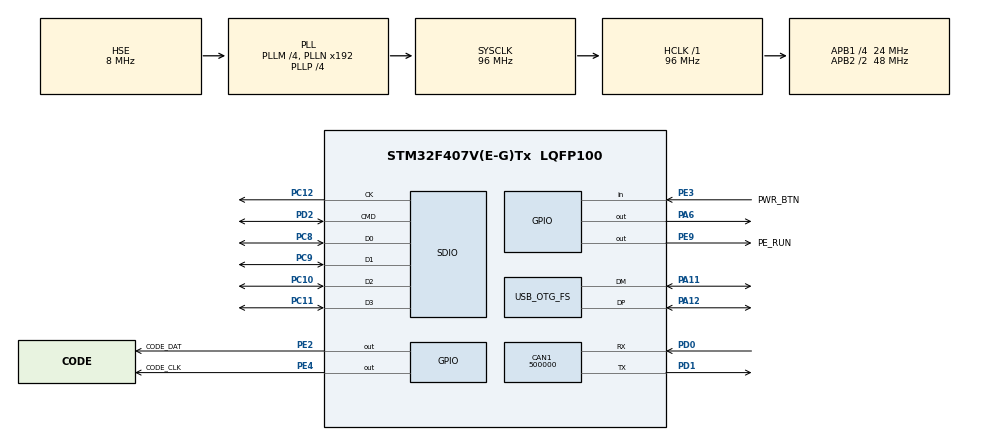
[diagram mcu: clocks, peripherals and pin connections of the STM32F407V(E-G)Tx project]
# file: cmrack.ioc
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Mcu.Family=STM32F4
PH0-OSC_IN.Signal=RCC_OSC_IN
RCC.CortexFreq_Value=96000000
PC12.Signal=SDIO_CK
PC10.Signal=SDIO_D2
PE2.GPIO_Speed=GPIO_SPEED_FREQ_HIGH
PE9.GPIO_Speed=GPIO_SPEED_FREQ_HIGH
PA11.Mode=Host_Only
RCC.SYSCLKSource=RCC_SYSCLKSOURCE_PLLCLK
ProjectManager.StackSize=0x400
VP_FREERTOS_VS_CMSIS_V2.Mode=CMSIS_V2
FREERTOS.configENABLE_FPU=1
PA12.Signal=USB_OTG_FS_DP
RCC.HCLKFreq_Value=96000000
RCC.APB2TimFreq_Value=96000000
PD0.Signal=CAN1_RX
USB_HOST0.BSP.ip=GPIO
RCC.AHBFreq_Value=96000000
PH0-OSC_IN.Mode=HSE-External-Oscillator
RCC.HSE_VALUE=8000000
NVIC.TIM8_TRG_COM_TIM14_IRQn=true\:0\:0\:false\:false\:true\:false\:false\:true
USB_OTG_FS.phy_itface=HCD_PHY_EMBEDDED
PE9.Signal=GPIO_Output
PA14.Mode=Serial_Wire
PE4.GPIO_Speed=GPIO_SPEED_FREQ_HIGH
PE4.GPIO_Label=CODE_CLK
PC9.Mode=mmc_4_bits_Wide_bus
PE2.Signal=GPIO_Output
VP_SYS_VS_tim14.Mode=TIM14
PE4.Signal=GPIO_Output
PH1-OSC_OUT.Mode=HSE-External-Oscillator
USB_HOST0.BSP.i2caddr=0
Mcu.Package=LQFP100
PA6.Signal=GPIO_Output
NVIC.TimeBase=TIM8_TRG_COM_TIM14_IRQn
RCC.EnbaleCSS=true
NVIC.OTG_FS_IRQn=true\:5\:0\:false\:false\:true\:true\:false\:true
NVIC.TimeBaseIP=TIM14
USB_OTG_FS.VirtualMode=Host_Only
PC11.Mode=mmc_4_bits_Wide_bus
USB_HOST0.BSP.name=Drive_VBUS_FS
RCC.APB2CLKDivider=RCC_HCLK_DIV2
RCC.APB1TimFreq_Value=48000000
CAN1.CalculateTimeBit=1999.99
PE2.GPIO_Label=CODE_DAT
CAN1.CalculateTimeQuantum=666.6666666666666
FREERTOS.Tasks01=defaultTask,24,128,StartDefaultTask,Default,NULL,Dynamic,NULL,NULL
PC11.Signal=SDIO_D3
CAN1.CalculateBaudRate=500000
PC8.Signal=SDIO_D0
USB_HOST0.BSP.solution=PA6
PC10.Mode=mmc_4_bits_Wide_bus
USB_HOST.BSP.number=1
PD1.Signal=CAN1_TX
RCC.APB1CLKDivider=RCC_HCLK_DIV4
USB_HOST0.BSP.STBoard=false
PA13.Signal=SYS_JTMS-SWDIO
CAN1.BS2=CAN_BS2_1TQ
CAN1.BS1=CAN_BS1_1TQ
ProjectManager.TargetToolchain=SW4STM32
USB_HOST.USBH_HandleTypeDef-ALL_Classes_FS=hUsbHostFS
RCC.LSE_VALUE=32768
PE9.GPIO_Label=PE_RUN
VP_FATFS_VS_Generic.Mode=User_defined
PD2.Mode=mmc_4_bits_Wide_bus
PC12.Mode=mmc_4_bits_Wide_bus
board=custom
RCC.VCOOutputFreq_Value=384000000
USB_HOST.VirtualModeFS=All_Classes
PD1.Mode=CAN_Activate
RCC.APB2Freq_Value=48000000
USB_HOST0.BSP.api=Unknown
PE3.GPIO_PuPd=GPIO_NOPULL
PH1-OSC_OUT.Signal=RCC_OSC_OUT
PA13.Mode=Serial_Wire
Mcu.Name=STM32F407V(E-G)Tx
PD0.Mode=CAN_Activate
PC8.Mode=mmc_4_bits_Wide_bus
RCC.48MHZClocksFreq_Value=48000000
RCC.SYSCLKFreq_VALUE=96000000
PA12.Mode=Host_Only
PA11.Signal=USB_OTG_FS_DM
PA14.Signal=SYS_JTCK-SWCLK
ProjectManager.HeapSize=0x200
RCC.HSI_VALUE=16000000
RCC.PLLP=RCC_PLLP_DIV4
RCC.PLLQ=8
NVIC.PriorityGroup=NVIC_PRIORITYGROUP_4
RCC.PLLM=4
PE3.Signal=GPIO_Input
PE3.GPIO_Label=PWR_BTN
PC9.Signal=SDIO_D1
PE9.GPIO_ModeDefaultOutputPP=GPIO_MODE_OUTPUT_OD
VP_USB_HOST_VS_USB_HOST_ALL_CLASS_FS.Mode=ALL_Classes_FS
PD2.Signal=SDIO_CMD
RCC.APB1Freq_Value=24000000
USB_HOST0.BSP.mode=Output
USB_HOST0.BSP.instance=PA6

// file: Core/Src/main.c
/* USER CODE BEGIN Header */
/**
  ******************************************************************************
  * @file           : main.c
  * @brief          : Main program body
  ******************************************************************************
  * @attention
  *
  * <h2><center>&copy; Copyright (c) 2021 STMicroelectronics.
  * All rights reserved.</center></h2>
  *
  * This software component is licensed by ST under Ultimate Liberty license
  * SLA0044, the "License"; You may not use this file except in compliance with
  * the License. You may obtain a copy of the License at:
  *                             www.st.com/SLA0044
  *
  ******************************************************************************
  */
/* USER CODE END Header */
#include <stm32f4xx_hal.h>
#include "main.h"
#include "cmsis_os.h"
#include "fatfs.h"
#include "usb_host.h"

CAN_HandleTypeDef hcan1;

MMC_HandleTypeDef hmmc;

/* Definitions for defaultTask */
osThreadId_t defaultTaskHandle;
const osThreadAttr_t defaultTask_attributes = {
        .name = "defaultTask",
        .priority = (osPriority_t) osPriorityNormal,
        .stack_size = 128 * 4
};

void SystemClock_Config(void);

static void MX_GPIO_Init(void);

static void MX_CAN1_Init(void);

static void MX_SDIO_MMC_Init(void);

void StartDefaultTask(void *argument) __noreturn;

int main(void) {

    /* MCU Configuration--------------------------------------------------------*/

    /* Reset of all peripherals, Initializes the Flash interface and the Systick. */
    HAL_Init();

    /* Configure the system clock */
    SystemClock_Config();

    /* USER CODE BEGIN SysInit */
    CLEAR_CODE();
    /* USER CODE END SysInit */

    /* Initialize all configured peripherals */
    MX_GPIO_Init();
    MX_CAN1_Init();
    MX_SDIO_MMC_Init();
    MX_FATFS_Init();

    /* USER CODE BEGIN 2 */
    write_code(1);
    HAL_Delay(100);
    /* USER CODE END 2 */

    /* Init scheduler */
    osKernelInitialize();

    /* Create the thread(s) */
    /* creation of defaultTask */
    defaultTaskHandle = osThreadNew(StartDefaultTask, NULL, &defaultTask_attributes);

    /* Start scheduler */
    osKernelStart();

    /* We should never get here as control is now taken by the scheduler */
    /* Infinite loop */
    /* USER CODE BEGIN WHILE */
    Error_Handler();
    /* USER CODE END 3 */
}

void SystemClock_Config(void) {
    RCC_OscInitTypeDef RCC_OscInitStruct = {0};
    RCC_ClkInitTypeDef RCC_ClkInitStruct = {0};

    /** Configure the main internal regulator output voltage
    */
    __HAL_RCC_PWR_CLK_ENABLE();
    __HAL_PWR_VOLTAGESCALING_CONFIG(PWR_REGULATOR_VOLTAGE_SCALE1);
    /** Initializes the RCC Oscillators according to the specified parameters
    * in the RCC_OscInitTypeDef structure.
    */
    RCC_OscInitStruct.OscillatorType = RCC_OSCILLATORTYPE_HSE;
    RCC_OscInitStruct.HSEState = RCC_HSE_ON;
    RCC_OscInitStruct.PLL.PLLState = RCC_PLL_ON;
    RCC_OscInitStruct.PLL.PLLSource = RCC_PLLSOURCE_HSE;
    RCC_OscInitStruct.PLL.PLLM = 4;
    RCC_OscInitStruct.PLL.PLLN = 192;
    RCC_OscInitStruct.PLL.PLLP = RCC_PLLP_DIV4;
    RCC_OscInitStruct.PLL.PLLQ = 8;
    if (HAL_RCC_OscConfig(&RCC_OscInitStruct) != HAL_OK) {
        Error_Handler();
    }
    /** Initializes the CPU, AHB and APB buses clocks
    */
    RCC_ClkInitStruct.ClockType = RCC_CLOCKTYPE_HCLK | RCC_CLOCKTYPE_SYSCLK
                                  | RCC_CLOCKTYPE_PCLK1 | RCC_CLOCKTYPE_PCLK2;
    RCC_ClkInitStruct.SYSCLKSource = RCC_SYSCLKSOURCE_PLLCLK;
    RCC_ClkInitStruct.AHBCLKDivider = RCC_SYSCLK_DIV1;
    RCC_ClkInitStruct.APB1CLKDivider = RCC_HCLK_DIV4;
    RCC_ClkInitStruct.APB2CLKDivider = RCC_HCLK_DIV2;

    if (HAL_RCC_ClockConfig(&RCC_ClkInitStruct, FLASH_LATENCY_3) != HAL_OK) {
        Error_Handler();
    }
    /** Enables the Clock Security System
    */
    HAL_RCC_EnableCSS();
}

static void MX_CAN1_Init(void) {

    hcan1.Instance = CAN1;
    hcan1.Init.Prescaler = 16;
    hcan1.Init.Mode = CAN_MODE_NORMAL;
    hcan1.Init.SyncJumpWidth = CAN_SJW_1TQ;
    hcan1.Init.TimeSeg1 = CAN_BS1_1TQ;
    hcan1.Init.TimeSeg2 = CAN_BS2_1TQ;
    hcan1.Init.TimeTriggeredMode = DISABLE;
    hcan1.Init.AutoBusOff = DISABLE;
    hcan1.Init.AutoWakeUp = DISABLE;
    hcan1.Init.AutoRetransmission = DISABLE;
    hcan1.Init.ReceiveFifoLocked = DISABLE;
    hcan1.Init.TransmitFifoPriority = DISABLE;
    if (HAL_CAN_Init(&hcan1) != HAL_OK) {
        Error_Handler();
    }

}

static void MX_SDIO_MMC_Init(void) {

    hmmc.Instance = SDIO;
    hmmc.Init.ClockEdge = SDIO_CLOCK_EDGE_RISING;
    hmmc.Init.ClockBypass = SDIO_CLOCK_BYPASS_DISABLE;
    hmmc.Init.ClockPowerSave = SDIO_CLOCK_POWER_SAVE_DISABLE;
    hmmc.Init.BusWide = SDIO_BUS_WIDE_1B;
    hmmc.Init.HardwareFlowControl = SDIO_HARDWARE_FLOW_CONTROL_DISABLE;
    hmmc.Init.ClockDiv = 0;
    if (HAL_MMC_Init(&hmmc) != HAL_OK) {
        Error_Handler();
    }
    if (HAL_MMC_ConfigWideBusOperation(&hmmc, SDIO_BUS_WIDE_4B) != HAL_OK) {
        Error_Handler();
    }

}

static void MX_GPIO_Init(void) {
    GPIO_InitTypeDef GPIO_InitStruct = {0};

    /* GPIO Ports Clock Enable */
    __HAL_RCC_GPIOE_CLK_ENABLE();
    __HAL_RCC_GPIOH_CLK_ENABLE();
    __HAL_RCC_GPIOA_CLK_ENABLE();
    __HAL_RCC_GPIOC_CLK_ENABLE();
    __HAL_RCC_GPIOD_CLK_ENABLE();

    /*Configure GPIO pin Output Level */
    HAL_GPIO_WritePin(GPIOE, CODE_DAT_Pin | CODE_CLK_Pin | PE_RUN_Pin, GPIO_PIN_RESET);

    /*Configure GPIO pin Output Level */
    HAL_GPIO_WritePin(GPIOA, GPIO_PIN_6, GPIO_PIN_RESET);

    /*Configure GPIO pins : CODE_DAT_Pin CODE_CLK_Pin */
    GPIO_InitStruct.Pin = CODE_DAT_Pin | CODE_CLK_Pin;
    GPIO_InitStruct.Mode = GPIO_MODE_OUTPUT_PP;
    GPIO_InitStruct.Pull = GPIO_NOPULL;
    GPIO_InitStruct.Speed = GPIO_SPEED_FREQ_HIGH;
    HAL_GPIO_Init(GPIOE, &GPIO_InitStruct);

    /*Configure GPIO pin : PWR_BTN_Pin */
    GPIO_InitStruct.Pin = PWR_BTN_Pin;
    GPIO_InitStruct.Mode = GPIO_MODE_INPUT;
    GPIO_InitStruct.Pull = GPIO_NOPULL;
    HAL_GPIO_Init(PWR_BTN_GPIO_Port, &GPIO_InitStruct);

    /*Configure GPIO pin : PA6 */
    GPIO_InitStruct.Pin = GPIO_PIN_6;
    GPIO_InitStruct.Mode = GPIO_MODE_OUTPUT_PP;
    GPIO_InitStruct.Pull = GPIO_NOPULL;
    GPIO_InitStruct.Speed = GPIO_SPEED_FREQ_LOW;
    HAL_GPIO_Init(GPIOA, &GPIO_InitStruct);

    /*Configure GPIO pin : PE_RUN_Pin */
    GPIO_InitStruct.Pin = PE_RUN_Pin;
    GPIO_InitStruct.Mode = GPIO_MODE_OUTPUT_OD;
    GPIO_InitStruct.Pull = GPIO_NOPULL;
    GPIO_InitStruct.Speed = GPIO_SPEED_FREQ_HIGH;
    HAL_GPIO_Init(PE_RUN_GPIO_Port, &GPIO_InitStruct);

}

void StartDefaultTask(void *argument) {
    /* init code for USB_HOST */
    MX_USB_HOST_Init();
    /* USER CODE BEGIN 5 */
    /* Infinite loop */
    write_code(0x02);
    for (;;) {
        osDelay(1000);
    }
    /* USER CODE END 5 */
}

void HAL_TIM_PeriodElapsedCallback(TIM_HandleTypeDef *htim) {
    if (htim->Instance == TIM14) {
        HAL_IncTick();
    }
}

//void Error_Handler(void)
//{
//  /* USER CODE BEGIN Error_Handler_Debug */
////  /* User can add his own implementation to report the HAL error return state */
////  __disable_irq();
////  while (1)
////  {
////  }
//  /* USER CODE END Error_Handler_Debug */
//}

/************************ (C) COPYRIGHT STMicroelectronics *****END OF FILE****/
